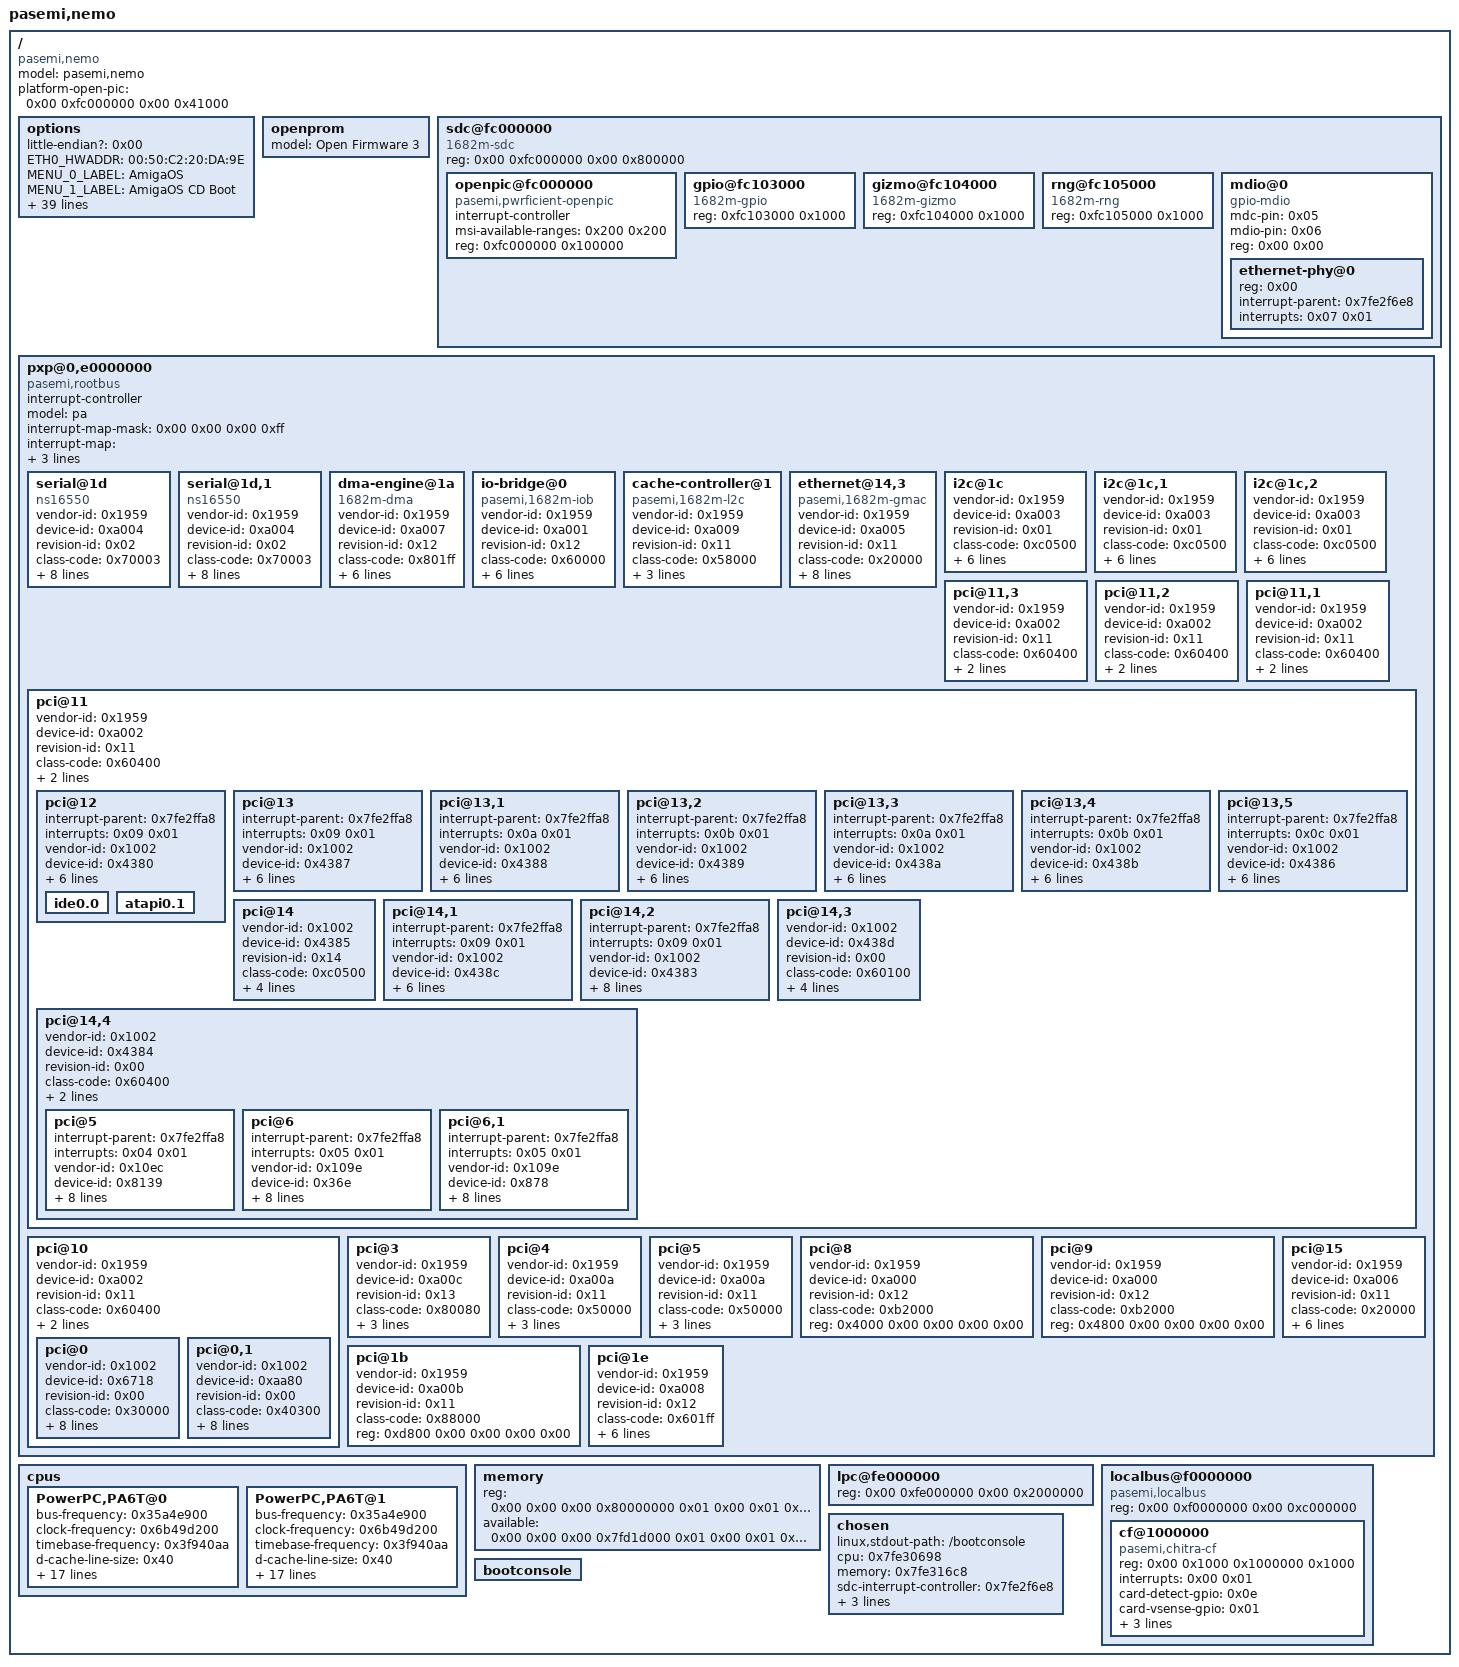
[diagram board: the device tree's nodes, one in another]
/dts-v1/;

/ {
	#interrupt-cells = <0x02>;
	#address-cells = <0x02>;
	#size-cells = <0x02>;
	model = "pasemi,nemo";
	device_type = "bootrom";
	compatible = "pasemi,nemo\0pasemi,pa6t-1682m\0PA6T-1682M\0pasemi,pwrficient\0pasemi";
	platform-open-pic = <0x00 0xfc000000 0x00 0x41000>;
	phandle = <0x7fdff018>;

	options {
		little-endian? = <0x00>;
		ETH0_HWADDR = "00:50:C2:20:DA:9E";
		MENU_0_LABEL = "AmigaOS";
		MENU_1_LABEL = "AmigaOS CD Boot";
		MENU_0_COMMAND = "setenv amigaboot_quiet Y ;boot -fs=amigafs ide0.0:amigaboot.of";
		MENU_1_COMMAND = "setenv amigaboot_quiet Y ;boot -fs=iso atapi0.1:amigaboot.of";
		MENU_DEFAULT = [30 00];
		os4_commandline = "DEBUGLEVEL=0 SERIAL";
		speed = "set pmu -astate=A4";
		MENU_TIMEOUT = [36 00];
		STARTUP = "speed;menu";
		MENU_4_LABEL = "SliTaz Snapshot 25 Kernel 3.13.14";
		MENU_4_COMMAND = "set pmu -astate=A4 ; ramdisk -z -addr=0x24000000 -fatfs cf0:slitaz25.gz ; boot -elf -noints -fatfs cf0:vmlinux-3.13.14";
		MENU_8_LABEL = "ubuntu MATE 16.04.2 LTS Kernel 4.9";
		MENU_8_COMMAND = "set pmu -astate=A4 ; setenv bootargs \"root=/dev/sdb1 quiet ro splash\" ; boot -elf -noints -fatfs cf0:vmlinux-4.9";
		MENU_2_LABEL = "Debian Sid/experimental Kernel 4.9";
		MENU_2_COMMAND = "set pmu -astate=A4 ; setenv bootargs \"root=/dev/sda4\" ; boot -elf -noints -fatfs cf0:vmlinux-4.9";
		MENU_9_LABEL = "openSUSE Tumbleweed Kernel 4.14";
		MENU_9_COMMAND = "set pmu -astate=A4 ; setenv bootargs \"root=/dev/sdb6 splash=silent\" ; boot -elf -noints -fatfs cf0:vmlinux-4.14";
		MENU_7_LABEL = "openSUSE 11.1 Kernel 4.17";
		MENU_7_COMMAND = "set pmu -astate=A4 ; setenv bootargs \"root=/dev/sdb5\" ; boot -elf -noints -fatfs cf0:vmlinux-4.17";
		MENU_6_LABEL = "Fienix Linux Kernel 4.20";
		MENU_6_COMMAND = "set pmu -astate=A4 ; setenv bootargs \"root=/dev/sdb4\" ; boot -elf -noints -z -fatfs cf0:zImage-4.20";
		MENU_5_LABEL = "Ubuntu 10.04.4 LTS kernel 4.20";
		MENU_5_COMMAND = "set pmu -astate=A4 ; setenv bootargs \"root=/dev/sdb3 quiet ro splash\" ; boot -elf -noints -z -fatfs cf0:zImage-4.20";
		framebuffer = "800/600/8/0x90000000/832";
		BOOT_CONSOLE = "pcconsole0";
		CFE_VERSION = "PAS-2.0.30";
		CFE_BOARDNAME = "NEMO";
		CFE_MEMORYSIZE = "8192";
		bootargs = "root=/dev/sdb4";
		phandle = <0x7fe2f1f0>;
	};

	openprom {
		device_type = "BootROM";
		model = "Open Firmware 3";
		phandle = <0x7fe2f2f0>;
	};

	sdc@fc000000 {
		device_type = "sdc";
		#address-cells = <0x01>;
		#size-cells = <0x01>;
		compatible = "1682m-sdc\0pasemi,pwrficient-sdc\0pasemi,sdc";
		reg = <0x00 0xfc000000 0x00 0x800000>;
		phandle = <0x7fe2f458>;

		openpic@fc000000 {
			device_type = "open-pic";
			compatible = "pasemi,pwrficient-openpic\0chrp,open-pic";
			interrupt-controller;
			#address-cells = <0x00>;
			#interrupt-cells = <0x02>;
			msi-available-ranges = <0x200 0x200>;
			reg = <0xfc000000 0x100000>;
			phandle = <0x7fe2f6e8>;
		};

		gpio@fc103000 {
			device_type = "gpio";
			compatible = "1682m-gpio\0pasemi,pwrficient-gpio\0pasemi,gpio";
			reg = <0xfc103000 0x1000>;
			phandle = <0x7fe2fa18>;
		};

		gizmo@fc104000 {
			device_type = "gizmo";
			compatible = "1682m-gizmo\0pasemi,pwrficient-gizmo\0pasemi,gizmo";
			reg = <0xfc104000 0x1000>;
			phandle = <0x7fe2fbf0>;
		};

		rng@fc105000 {
			device_type = "rng";
			compatible = "1682m-rng\0pasemi,pwrficient-rng\0pasemi,rng";
			reg = <0xfc105000 0x1000>;
			phandle = <0x7fe2fdd0>;
		};

		mdio@0 {
			compatible = "gpio-mdio";
			#address-cells = <0x01>;
			#size-cells = <0x00>;
			mdc-pin = <0x05>;
			mdio-pin = <0x06>;
			reg = <0x00 0x00>;
			phandle = <0x7fe3dd68>;

			ethernet-phy@0 {
				reg = <0x00>;
				interrupt-parent = <0x7fe2f6e8>;
				interrupts = <0x07 0x01>;
				phandle = <0x7fe3e028>;
			};
		};
	};

	pxp@0,e0000000 {
		interrupt-controller;
		device_type = "pci";
		#interrupt-cells = <0x01>;
		#address-cells = <0x03>;
		#size-cells = <0x02>;
		model = "pa";
		compatible = "pasemi,rootbus\0pa-pxp";
		interrupt-map-mask = <0x00 0x00 0x00 0xff>;
		interrupt-map = <0x00 0x00 0x00 0x30 0x7fe2f6e8 0x30 0x01 0x00 0x00 0x00 0x31 0x7fe2f6e8 0x31 0x01 0x00 0x00 0x00 0x32 0x7fe2f6e8 0x32 0x01 0x00 0x00 0x00 0x33 0x7fe2f6e8 0x33 0x01>;
		bus-range = <0x00 0xff>;
		ranges = <0x00 0x00 0xe0000000 0x00 0xe0000000 0x00 0x10000000 0x1000000 0x00 0x00 0x00 0xfc800000 0x00 0x800000 0x2000000 0x00 0x80000000 0x00 0x80000000 0x00 0x60000000 0x2000000 0x00 0xe0000000 0x00 0xe0000000 0x00 0x100000 0x2000000 0x00 0xfd800000 0x00 0xfd800000 0x00 0x1000 0x2000000 0x800 0x00 0x800 0x00 0x400 0x00>;
		reg = <0x00 0xe0000000 0x00 0x10000000>;
		phandle = <0x7fe2ffa8>;

		serial@1d {
			device_type = "serial";
			vendor-id = <0x1959>;
			device-id = <0xa004>;
			revision-id = <0x02>;
			class-code = <0x70003>;
			reg = <0xe800 0x00 0x00 0x00 0x00 0x100e810 0x00 0x00 0x00 0x08>;
			assigned-addresses = <0x8100e810 0x00 0x7f03f8 0x00 0x08>;
			interrupt-parent = <0x7fe2f6e8>;
			interrupts = <0x49 0x01>;
			clock-frequency = <0x7f28155>;
			current-speed = <0x1c200>;
			compatible = "ns16550\0pciclass,0700";
			phandle = <0x7fe318a8>;
		};

		serial@1d,1 {
			device_type = "serial";
			vendor-id = <0x1959>;
			device-id = <0xa004>;
			revision-id = <0x02>;
			class-code = <0x70003>;
			reg = <0xe900 0x00 0x00 0x00 0x00 0x100e910 0x00 0x00 0x00 0x08>;
			assigned-addresses = <0x8100e910 0x00 0x7f02f8 0x00 0x08>;
			interrupt-parent = <0x7fe2f6e8>;
			interrupts = <0x4a 0x01>;
			clock-frequency = <0x7f28155>;
			current-speed = <0x1c200>;
			compatible = "ns16550\0pciclass,0700";
			phandle = <0x7fe31db0>;
		};

		dma-engine@1a {
			device_type = "dma-engine";
			vendor-id = <0x1959>;
			device-id = <0xa007>;
			revision-id = <0x12>;
			class-code = <0x801ff>;
			reg = <0xd000 0x00 0x00 0x00 0x00 0x82000000 0x00 0xe00d0000 0x00 0x1000>;
			assigned-addresses = <0x82000000 0x00 0xe00d0000 0x00 0x1000>;
			interrupt-parent = <0x7fe2f6e8>;
			interrupts = <0x80 0x01>;
			compatible = "1682m-dma\0pasemi,dma-engine";
			phandle = <0x7fe322b8>;
		};

		io-bridge@0 {
			device_type = "isa";
			vendor-id = <0x1959>;
			device-id = <0xa001>;
			revision-id = <0x12>;
			class-code = <0x60000>;
			reg = <0x00 0x00 0x00 0x00 0x00 0x82000000 0x00 0xe0000000 0x00 0x2000 0xc2000000 0x00 0xfd800000 0x00 0x1000>;
			assigned-addresses = <0x82000000 0x00 0xe0000000 0x00 0x2000 0xc2000000 0x00 0xfd800000 0x00 0x1000>;
			interrupt-parent = <0x7fe2f6e8>;
			interrupts = <0x56 0x01>;
			compatible = "pasemi,1682m-iob\0pasemi,io-bridge";
			phandle = <0x7fe32728>;
		};

		cache-controller@1 {
			device_type = "cache-controller";
			vendor-id = <0x1959>;
			device-id = <0xa009>;
			revision-id = <0x11>;
			class-code = <0x58000>;
			reg = <0x800 0x00 0x00 0x00 0x00>;
			interrupt-parent = <0x7fe2f6e8>;
			interrupts = <0x52 0x01>;
			compatible = "pasemi,1682m-l2c\0pasemi,l2c";
			phandle = <0x7fe32bc8>;
		};

		ethernet@14,3 {
			device_type = "ethernet";
			vendor-id = <0x1959>;
			device-id = <0xa005>;
			revision-id = <0x11>;
			class-code = <0x20000>;
			reg = <0xa300 0x00 0x00 0x00 0x00 0x82000000 0x00 0xe00a3000 0x00 0x1000>;
			assigned-addresses = <0x82000000 0x00 0xe00a3000 0x00 0x1000>;
			interrupt-parent = <0x7fe2f6e8>;
			interrupts = <0x43 0x01>;
			local-mac-address = [02 00 e0 0a 30 00];
			compatible = "pasemi,1682m-gmac\0pasemi,ethernet";
			phy-handle = <0x7fe3e028>;
			phandle = <0x7fe32fd0>;
		};

		i2c@1c {
			device_type = "i2c";
			vendor-id = <0x1959>;
			device-id = <0xa003>;
			revision-id = <0x01>;
			class-code = <0xc0500>;
			reg = <0xe000 0x00 0x00 0x00 0x00 0x100e010 0x00 0x00 0x00 0x40>;
			assigned-addresses = <0x8100e010 0x00 0x7f0200 0x00 0x40>;
			interrupt-parent = <0x7fe2f6e8>;
			interrupts = <0x46 0x01>;
			phandle = <0x7fe334a0>;
		};

		i2c@1c,1 {
			device_type = "i2c";
			vendor-id = <0x1959>;
			device-id = <0xa003>;
			revision-id = <0x01>;
			class-code = <0xc0500>;
			reg = <0xe100 0x00 0x00 0x00 0x00 0x100e110 0x00 0x00 0x00 0x40>;
			assigned-addresses = <0x8100e110 0x00 0x7f0240 0x00 0x40>;
			interrupt-parent = <0x7fe2f6e8>;
			interrupts = <0x47 0x01>;
			phandle = <0x7fe33890>;
		};

		i2c@1c,2 {
			device_type = "i2c";
			vendor-id = <0x1959>;
			device-id = <0xa003>;
			revision-id = <0x01>;
			class-code = <0xc0500>;
			reg = <0xe200 0x00 0x00 0x00 0x00 0x100e210 0x00 0x00 0x00 0x40>;
			assigned-addresses = <0x8100e210 0x00 0x7f0280 0x00 0x40>;
			interrupt-parent = <0x7fe2f6e8>;
			interrupts = <0x48 0x01>;
			phandle = <0x7fe33c80>;
		};

		pci@11,3 {
			device_type = "pci";
			vendor-id = <0x1959>;
			device-id = <0xa002>;
			revision-id = <0x11>;
			class-code = <0x60400>;
			#address-cells = <0x03>;
			#size-cells = <0x02>;
			#interrupt-cells = <0x01>;
			bus-range = <0x09 0x09>;
			reg = <0x8b00 0x00 0x00 0x00 0x00>;
			phandle = <0x7fe36230>;
		};

		pci@11,2 {
			device_type = "pci";
			vendor-id = <0x1959>;
			device-id = <0xa002>;
			revision-id = <0x11>;
			class-code = <0x60400>;
			#address-cells = <0x03>;
			#size-cells = <0x02>;
			#interrupt-cells = <0x01>;
			bus-range = <0x08 0x08>;
			reg = <0x8a00 0x00 0x00 0x00 0x00>;
			phandle = <0x7fe36658>;
		};

		pci@11,1 {
			device_type = "pci";
			vendor-id = <0x1959>;
			device-id = <0xa002>;
			revision-id = <0x11>;
			class-code = <0x60400>;
			#address-cells = <0x03>;
			#size-cells = <0x02>;
			#interrupt-cells = <0x01>;
			bus-range = <0x07 0x07>;
			reg = <0x8900 0x00 0x00 0x00 0x00>;
			phandle = <0x7fe36a80>;
		};

		pci@11 {
			device_type = "pci";
			vendor-id = <0x1959>;
			device-id = <0xa002>;
			revision-id = <0x11>;
			class-code = <0x60400>;
			#address-cells = <0x03>;
			#size-cells = <0x02>;
			#interrupt-cells = <0x01>;
			bus-range = <0x05 0x06>;
			reg = <0x8800 0x00 0x00 0x00 0x00>;
			ranges = <0x1000000 0x00 0x00 0x1000000 0x00 0x00 0x00 0x4000 0x2000000 0x00 0xa0100000 0x2000000 0x00 0xa0100000 0x00 0x300000>;
			phandle = <0x7fe36ea8>;

			pci@12 {
				interrupt-parent = <0x7fe2ffa8>;
				interrupts = <0x09 0x01>;
				device_type = "pci";
				vendor-id = <0x1002>;
				device-id = <0x4380>;
				revision-id = <0x00>;
				class-code = <0x1018f>;
				reg = <0x59000 0x00 0x00 0x00 0x00 0x1059010 0x00 0x00 0x00 0x08 0x1059014 0x00 0x00 0x00 0x04 0x1059018 0x00 0x00 0x00 0x08 0x105901c 0x00 0x00 0x00 0x04 0x1059020 0x00 0x00 0x00 0x10 0x2059024 0x00 0x00 0x00 0x400>;
				assigned-addresses = <0x81059010 0x00 0x1040 0x00 0x08 0x81059014 0x00 0x105c 0x00 0x04 0x81059018 0x00 0x1048 0x00 0x08 0x8105901c 0x00 0x1058 0x00 0x04 0x81059020 0x00 0x1010 0x00 0x10 0x82059024 0x00 0xa0209000 0x00 0x400>;
				phandle = <0x7fe39c70>;

				ide0.0 {
					device_type = "block";
					phandle = <0x7fe3a128>;
				};

				atapi0.1 {
					device_type = "block";
					phandle = <0x7fe3a228>;
				};
			};

			pci@13 {
				interrupt-parent = <0x7fe2ffa8>;
				interrupts = <0x09 0x01>;
				device_type = "pci";
				vendor-id = <0x1002>;
				device-id = <0x4387>;
				revision-id = <0x00>;
				class-code = <0xc0310>;
				reg = <0x59800 0x00 0x00 0x00 0x00 0x2059810 0x00 0x00 0x00 0x1000>;
				assigned-addresses = <0x82059810 0x00 0xa0207000 0x00 0x1000>;
				phandle = <0x7fe3a330>;
			};

			pci@13,1 {
				interrupt-parent = <0x7fe2ffa8>;
				interrupts = <0x0a 0x01>;
				device_type = "pci";
				vendor-id = <0x1002>;
				device-id = <0x4388>;
				revision-id = <0x00>;
				class-code = <0xc0310>;
				reg = <0x59900 0x00 0x00 0x00 0x00 0x2059910 0x00 0x00 0x00 0x1000>;
				assigned-addresses = <0x82059910 0x00 0xa0208000 0x00 0x1000>;
				phandle = <0x7fe3a720>;
			};

			pci@13,2 {
				interrupt-parent = <0x7fe2ffa8>;
				interrupts = <0x0b 0x01>;
				device_type = "pci";
				vendor-id = <0x1002>;
				device-id = <0x4389>;
				revision-id = <0x00>;
				class-code = <0xc0310>;
				reg = <0x59a00 0x00 0x00 0x00 0x00 0x2059a10 0x00 0x00 0x00 0x1000>;
				assigned-addresses = <0x82059a10 0x00 0xa0206000 0x00 0x1000>;
				phandle = <0x7fe3ab10>;
			};

			pci@13,3 {
				interrupt-parent = <0x7fe2ffa8>;
				interrupts = <0x0a 0x01>;
				device_type = "pci";
				vendor-id = <0x1002>;
				device-id = <0x438a>;
				revision-id = <0x00>;
				class-code = <0xc0310>;
				reg = <0x59b00 0x00 0x00 0x00 0x00 0x2059b10 0x00 0x00 0x00 0x1000>;
				assigned-addresses = <0x82059b10 0x00 0xa0205000 0x00 0x1000>;
				phandle = <0x7fe3af00>;
			};

			pci@13,4 {
				interrupt-parent = <0x7fe2ffa8>;
				interrupts = <0x0b 0x01>;
				device_type = "pci";
				vendor-id = <0x1002>;
				device-id = <0x438b>;
				revision-id = <0x00>;
				class-code = <0xc0310>;
				reg = <0x59c00 0x00 0x00 0x00 0x00 0x2059c10 0x00 0x00 0x00 0x1000>;
				assigned-addresses = <0x82059c10 0x00 0xa0204000 0x00 0x1000>;
				phandle = <0x7fe3b2f0>;
			};

			pci@13,5 {
				interrupt-parent = <0x7fe2ffa8>;
				interrupts = <0x0c 0x01>;
				device_type = "pci";
				vendor-id = <0x1002>;
				device-id = <0x4386>;
				revision-id = <0x00>;
				class-code = <0xc0320>;
				reg = <0x59d00 0x00 0x00 0x00 0x00 0x2059d10 0x00 0x00 0x00 0x100>;
				assigned-addresses = <0x82059d10 0x00 0xa0209800 0x00 0x100>;
				phandle = <0x7fe3b6e0>;
			};

			pci@14 {
				device_type = "pci";
				vendor-id = <0x1002>;
				device-id = <0x4385>;
				revision-id = <0x14>;
				class-code = <0xc0500>;
				reg = <0x5a000 0x00 0x00 0x00 0x00 0x105a010 0x00 0x00 0x00 0x10 0x205a014 0x00 0x00 0x00 0x400>;
				assigned-addresses = <0x8105a010 0x00 0x1020 0x00 0x10 0x8205a014 0x00 0xa0209400 0x00 0x400>;
				phandle = <0x7fe3bad0>;
			};

			pci@14,1 {
				interrupt-parent = <0x7fe2ffa8>;
				interrupts = <0x09 0x01>;
				device_type = "pci";
				vendor-id = <0x1002>;
				device-id = <0x438c>;
				revision-id = <0x00>;
				class-code = <0x10183>;
				reg = <0x5a100 0x00 0x00 0x00 0x00 0x105a110 0x00 0x00 0x00 0x08 0x105a114 0x00 0x00 0x00 0x04 0x105a118 0x00 0x00 0x00 0x08 0x105a11c 0x00 0x00 0x00 0x04 0x105a120 0x00 0x00 0x00 0x10>;
				assigned-addresses = <0x8105a110 0x00 0x1030 0x00 0x08 0x8105a114 0x00 0x1054 0x00 0x04 0x8105a118 0x00 0x1038 0x00 0x08 0x8105a11c 0x00 0x1050 0x00 0x04 0x8105a120 0x00 0x1000 0x00 0x10>;
				phandle = <0x7fe3be38>;
			};

			pci@14,2 {
				interrupt-parent = <0x7fe2ffa8>;
				interrupts = <0x09 0x01>;
				device_type = "pci";
				vendor-id = <0x1002>;
				device-id = <0x4383>;
				revision-id = <0x00>;
				class-code = <0x40300>;
				subsystem-vendor-id = <0x1888>;
				subsystem-id = <0x1000>;
				reg = <0x5a200 0x00 0x00 0x00 0x00 0x205a210 0x00 0x00 0x00 0x4000>;
				assigned-addresses = <0x8205a210 0x00 0xa0200000 0x00 0x4000>;
				phandle = <0x7fe3c2c8>;
			};

			pci@14,3 {
				device_type = "pci";
				vendor-id = <0x1002>;
				device-id = <0x438d>;
				revision-id = <0x00>;
				class-code = <0x60100>;
				reg = <0x5a300 0x00 0x00 0x00 0x00 0x205a310 0x00 0x00 0x00 0x100000>;
				assigned-addresses = <0x8205a310 0x00 0xa0100000 0x00 0x100000>;
				phandle = <0x7fe3c768>;
			};

			pci@14,4 {
				device_type = "pci";
				vendor-id = <0x1002>;
				device-id = <0x4384>;
				revision-id = <0x00>;
				class-code = <0x60400>;
				#address-cells = <0x03>;
				#size-cells = <0x02>;
				#interrupt-cells = <0x01>;
				bus-range = <0x06 0x06>;
				reg = <0x5a400 0x00 0x00 0x00 0x00>;
				ranges = <0x1000000 0x00 0x3000 0x1000000 0x00 0x3000 0x00 0x1000 0x2000000 0x00 0xa0300000 0x2000000 0x00 0xa0300000 0x00 0x100000>;
				phandle = <0x7fe3caa8>;

				pci@5 {
					interrupt-parent = <0x7fe2ffa8>;
					interrupts = <0x04 0x01>;
					device_type = "pci";
					vendor-id = <0x10ec>;
					device-id = <0x8139>;
					revision-id = <0x10>;
					class-code = <0x20000>;
					subsystem-vendor-id = <0x10ec>;
					subsystem-id = <0x8139>;
					reg = <0x62800 0x00 0x00 0x00 0x00 0x1062810 0x00 0x00 0x00 0x100 0x2062814 0x00 0x00 0x00 0x100>;
					assigned-addresses = <0x81062810 0x00 0x3000 0x00 0x100 0x82062814 0x00 0xa0312000 0x00 0x100>;
					phandle = <0x7fe3cf60>;
				};

				pci@6 {
					interrupt-parent = <0x7fe2ffa8>;
					interrupts = <0x05 0x01>;
					device_type = "pci";
					vendor-id = <0x109e>;
					device-id = <0x36e>;
					revision-id = <0x11>;
					class-code = <0x40000>;
					subsystem-vendor-id = <0x70>;
					subsystem-id = <0x13eb>;
					reg = <0x63000 0x00 0x00 0x00 0x00 0x42063010 0x00 0x00 0x00 0x1000>;
					assigned-addresses = <0xc2063010 0x00 0xa0310000 0x00 0x1000>;
					phandle = <0x7fe3d428>;
				};

				pci@6,1 {
					interrupt-parent = <0x7fe2ffa8>;
					interrupts = <0x05 0x01>;
					device_type = "pci";
					vendor-id = <0x109e>;
					device-id = <0x878>;
					revision-id = <0x11>;
					class-code = <0x48000>;
					subsystem-vendor-id = <0x70>;
					subsystem-id = <0x13eb>;
					reg = <0x63100 0x00 0x00 0x00 0x00 0x42063110 0x00 0x00 0x00 0x1000>;
					assigned-addresses = <0xc2063110 0x00 0xa0311000 0x00 0x1000>;
					phandle = <0x7fe3d8c8>;
				};
			};
		};

		pci@10 {
			device_type = "pci";
			vendor-id = <0x1959>;
			device-id = <0xa002>;
			revision-id = <0x11>;
			class-code = <0x60400>;
			#address-cells = <0x03>;
			#size-cells = <0x02>;
			#interrupt-cells = <0x01>;
			bus-range = <0x01 0x01>;
			reg = <0x8000 0x00 0x00 0x00 0x00>;
			ranges = <0x1000000 0x00 0x2000 0x1000000 0x00 0x2000 0x00 0x1000 0x2000000 0x00 0x90000000 0x2000000 0x00 0x90000000 0x00 0x10100000>;
			phandle = <0x7fe37360>;

			pci@0 {
				device_type = "pci";
				vendor-id = <0x1002>;
				device-id = <0x6718>;
				revision-id = <0x00>;
				class-code = <0x30000>;
				subsystem-vendor-id = <0x1682>;
				subsystem-id = <0x3130>;
				reg = <0x10000 0x00 0x00 0x00 0x00 0x42010010 0x00 0x00 0x00 0x10000000 0x2010018 0x00 0x00 0x00 0x20000 0x1010020 0x00 0x00 0x00 0x100>;
				assigned-addresses = <0xc2010010 0x00 0x90000000 0x00 0x10000000 0x82010018 0x00 0xa0020000 0x00 0x20000 0x81010020 0x00 0x2000 0x00 0x100>;
				interrupt-parent = <0x7fe2f6e8>;
				interrupts = <0x30 0x01>;
				phandle = <0x7fe392e0>;
			};

			pci@0,1 {
				device_type = "pci";
				vendor-id = <0x1002>;
				device-id = <0xaa80>;
				revision-id = <0x00>;
				class-code = <0x40300>;
				subsystem-vendor-id = <0x1682>;
				subsystem-id = <0xaa80>;
				reg = <0x10100 0x00 0x00 0x00 0x00 0x2010110 0x00 0x00 0x00 0x4000>;
				assigned-addresses = <0x82010110 0x00 0xa0040000 0x00 0x4000>;
				interrupt-parent = <0x7fe2f6e8>;
				interrupts = <0x31 0x01>;
				phandle = <0x7fe397d0>;
			};
		};

		pci@3 {
			device_type = "pci";
			vendor-id = <0x1959>;
			device-id = <0xa00c>;
			revision-id = <0x13>;
			class-code = <0x80080>;
			reg = <0x1800 0x00 0x00 0x00 0x00>;
			interrupt-parent = <0x7fe2f6e8>;
			interrupts = <0x54 0x01>;
			phandle = <0x7fe37818>;
		};

		pci@4 {
			device_type = "pci";
			vendor-id = <0x1959>;
			device-id = <0xa00a>;
			revision-id = <0x11>;
			class-code = <0x50000>;
			reg = <0x2000 0x00 0x00 0x00 0x00>;
			interrupt-parent = <0x7fe2f6e8>;
			interrupts = <0x58 0x01>;
			phandle = <0x7fe37b90>;
		};

		pci@5 {
			device_type = "pci";
			vendor-id = <0x1959>;
			device-id = <0xa00a>;
			revision-id = <0x11>;
			class-code = <0x50000>;
			reg = <0x2800 0x00 0x00 0x00 0x00>;
			interrupt-parent = <0x7fe2f6e8>;
			interrupts = <0x5a 0x01>;
			phandle = <0x7fe37f08>;
		};

		pci@8 {
			device_type = "pci";
			vendor-id = <0x1959>;
			device-id = <0xa000>;
			revision-id = <0x12>;
			class-code = <0xb2000>;
			reg = <0x4000 0x00 0x00 0x00 0x00>;
			phandle = <0x7fe38280>;
		};

		pci@9 {
			device_type = "pci";
			vendor-id = <0x1959>;
			device-id = <0xa000>;
			revision-id = <0x12>;
			class-code = <0xb2000>;
			reg = <0x4800 0x00 0x00 0x00 0x00>;
			phandle = <0x7fe38548>;
		};

		pci@15 {
			device_type = "pci";
			vendor-id = <0x1959>;
			device-id = <0xa006>;
			revision-id = <0x11>;
			class-code = <0x20000>;
			reg = <0xa800 0x00 0x00 0x00 0x00 0x82000000 0x00 0xe00a8000 0x00 0x1000>;
			assigned-addresses = <0x82000000 0x00 0xe00a8000 0x00 0x1000>;
			interrupt-parent = <0x7fe2f6e8>;
			interrupts = <0x44 0x01>;
			phandle = <0x7fe38810>;
		};

		pci@1b {
			device_type = "pci";
			vendor-id = <0x1959>;
			device-id = <0xa00b>;
			revision-id = <0x11>;
			class-code = <0x88000>;
			reg = <0xd800 0x00 0x00 0x00 0x00>;
			phandle = <0x7fe38c00>;
		};

		pci@1e {
			device_type = "pci";
			vendor-id = <0x1959>;
			device-id = <0xa008>;
			revision-id = <0x12>;
			class-code = <0x601ff>;
			reg = <0xf000 0x00 0x00 0x00 0x00 0x100f010 0x00 0x00 0x00 0x100 0x100f014 0x00 0x00 0x00 0x100>;
			assigned-addresses = <0x8100f010 0x00 0x7f0400 0x00 0x100 0x8100f014 0x00 0x7f0500 0x00 0x100>;
			interrupt-parent = <0x7fe2f6e8>;
			interrupts = <0x51 0x01>;
			phandle = <0x7fe38ec8>;
		};
	};

	cpus {
		#address-cells = <0x01>;
		#size-cells = <0x00>;
		phandle = <0x7fe30540>;

		PowerPC,PA6T@0 {
			device_type = "cpu";
			bus-frequency = <0x35a4e900>;
			clock-frequency = <0x6b49d200>;
			timebase-frequency = <0x3f940aa>;
			d-cache-line-size = <0x40>;
			i-cache-line-size = <0x40>;
			d-cache-block-size = <0x40>;
			i-cache-block-size = <0x40>;
			ibm,segment-page-sizes = <0x0c 0x00 0x01 0x0c 0x00 0x0e 0x20 0x01 0x0e 0x01 0x10 0x110 0x01 0x10 0x03 0x12 0x130 0x01 0x12 0x0f 0x14 0x30 0x01 0x14 0x1f 0x18 0x100 0x01 0x18 0x00 0x1e 0x120 0x01 0x1e 0x3f>;
			ibm,processor-segment-sizes = <0x1c 0x28>;
			ibm,processor-page-sizes = <0x0c 0x0e 0x10 0x12 0x14 0x18 0x1e>;
			64-bit;
			cpu-version = <0x900102>;
			general-purpose;
			graphics;
			d-cache-size = <0x10000>;
			i-cache-size = <0x10000>;
			i-cache-sets = <0x02>;
			d-cache-sets = <0x02>;
			reg = <0x00>;
			phandle = <0x7fe30698>;
		};

		PowerPC,PA6T@1 {
			device_type = "cpu";
			bus-frequency = <0x35a4e900>;
			clock-frequency = <0x6b49d200>;
			timebase-frequency = <0x3f940aa>;
			d-cache-line-size = <0x40>;
			i-cache-line-size = <0x40>;
			d-cache-block-size = <0x40>;
			i-cache-block-size = <0x40>;
			ibm,segment-page-sizes = <0x0c 0x00 0x01 0x0c 0x00 0x0e 0x20 0x01 0x0e 0x01 0x10 0x110 0x01 0x10 0x03 0x12 0x130 0x01 0x12 0x0f 0x14 0x30 0x01 0x14 0x1f 0x18 0x100 0x01 0x18 0x00 0x1e 0x120 0x01 0x1e 0x3f>;
			ibm,processor-segment-sizes = <0x1c 0x28>;
			ibm,processor-page-sizes = <0x0c 0x0e 0x10 0x12 0x14 0x18 0x1e>;
			64-bit;
			cpu-version = <0x900102>;
			general-purpose;
			graphics;
			d-cache-size = <0x10000>;
			i-cache-size = <0x10000>;
			i-cache-sets = <0x02>;
			d-cache-sets = <0x02>;
			reg = <0x01>;
			phandle = <0x7fe30eb0>;
		};
	};

	memory {
		device_type = "memory";
		reg = <0x00 0x00 0x00 0x80000000 0x01 0x00 0x01 0x80000000>;
		available = <0x00 0x00 0x00 0x7fd1d000 0x01 0x00 0x01 0x80000000>;
		phandle = <0x7fe316c8>;
	};

	lpc@fe000000 {
		device_type = "lpc";
		#address-cells = <0x01>;
		#size-cells = <0x01>;
		reg = <0x00 0xfe000000 0x00 0x2000000>;
		ranges = <0xfe000000 0x00 0xfe000000 0x2000000>;
		phandle = <0x7fe34070>;
	};

	localbus@f0000000 {
		device_type = "localbus";
		compatible = "pasemi,localbus\0localbus";
		#interrupt-cells = <0x02>;
		#address-cells = <0x01>;
		#size-cells = <0x01>;
		reg = <0x00 0xf0000000 0x00 0xc000000>;
		ranges = <0x00 0x00 0xf0000000 0xc000000>;
		phandle = <0x7fe342e0>;

		cf@1000000 {
			device_type = "electra-cf";
			compatible = "pasemi,chitra-cf\0pasemi,electra-cf\0electra-cf";
			reg = <0x00 0x1000 0x1000000 0x1000>;
			interrupts = <0x00 0x01>;
			card-detect-gpio = <0x0e>;
			card-vsense-gpio = <0x01>;
			card-3v-gpio = <0x0a>;
			card-5v-gpio = <0x0b>;
			interrupt-parent = <0x7fe2f6e8>;
			phandle = <0x7fe3e238>;
		};
	};

	chosen {
		linux,stdout-path = "/bootconsole";
		cpu = <0x7fe30698>;
		memory = <0x7fe316c8>;
		sdc-interrupt-controller = <0x7fe2f6e8>;
		stdin = <0x7fe35818>;
		stdout = <0x7fe35818>;
		bootargs = "root=/dev/sdb4";
		phandle = <0x7fe34628>;
	};

	bootconsole {
		device_type = "bootconsole";
		phandle = <0x7fe35708>;
	};
};
